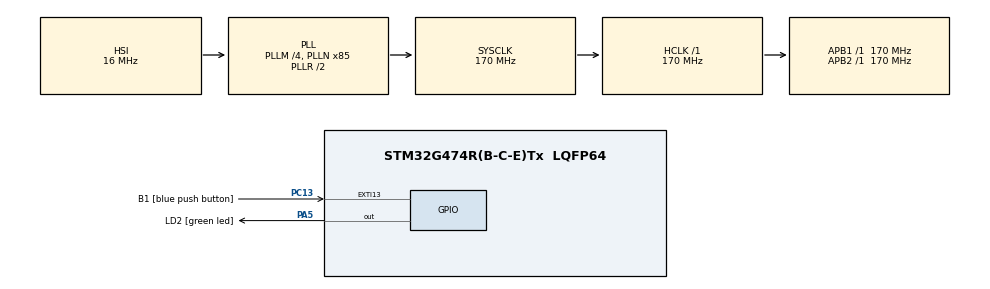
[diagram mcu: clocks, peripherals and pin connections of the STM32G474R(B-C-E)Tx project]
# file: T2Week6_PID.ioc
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ARM.CMSIS.5.7.0.CMSISJjCORE=true
ARM.CMSIS.5.7.0.CMSISJjDSP=Library
Mcu.Family=STM32G4
Mcu.Name=STM32G474R(B-C-E)Tx
Mcu.Package=LQFP64
NVIC.EXTI15_10_IRQn=true\:0\:0\:false\:false\:true\:true\:true\:true
NVIC.PriorityGroup=NVIC_PRIORITYGROUP_4
PA13.GPIO_Label=T_SWDIO
PA13.Mode=Trace_Asynchronous_SW
PA13.Signal=SYS_JTMS-SWDIO
PA14.GPIO_Label=T_SWCLK
PA14.Mode=Trace_Asynchronous_SW
PA14.Signal=SYS_JTCK-SWCLK
PA2.GPIO_Label=LPUART1_TX [STLINKV3E_VCP_RX]
PA2.Signal=LPUART1_TX
PA3.GPIO_Label=LPUART1_RX [STLINKV3E_VCP_TX]
PA3.Signal=LPUART1_RX
PA5.GPIO_Label=LD2 [green led]
PA5.Signal=GPIO_Output
PB3.GPIO_Label=T_SWO
PB3.Mode=Trace_Asynchronous_SW
PB3.Signal=SYS_JTDO-SWO
PC13.GPIO_Label=B1 [blue push button]
PC13.Signal=GPXTI13
PC14-OSC32_IN.GPIO_Label=RCC_OSC32_IN
PC14-OSC32_IN.Signal=RCC_OSC32_IN
PC15-OSC32_OUT.GPIO_Label=RCC_OSC32_OUT
PC15-OSC32_OUT.Signal=RCC_OSC32_OUT
PF0-OSC_IN.GPIO_Label=RCC_OSC_IN
PF0-OSC_IN.Signal=RCC_OSC_IN
PF1-OSC_OUT.GPIO_Label=RCC_OSC_OUT
PF1-OSC_OUT.Signal=RCC_OSC_OUT
ProjectManager.HeapSize=0x200
ProjectManager.StackSize=0x400
ProjectManager.TargetToolchain=STM32CubeIDE
RCC.ADC12Freq_Value=170000000
RCC.ADC345Freq_Value=170000000
RCC.AHBFreq_Value=170000000
RCC.APB1Freq_Value=170000000
RCC.APB1TimFreq_Value=170000000
RCC.APB2Freq_Value=170000000
RCC.APB2TimFreq_Value=170000000
RCC.CortexFreq_Value=170000000
RCC.EXTERNAL_CLOCK_VALUE=12288000
RCC.HCLKFreq_Value=170000000
RCC.HSE_VALUE=24000000
RCC.HSI48_VALUE=48000000
RCC.HSI_VALUE=16000000
RCC.LSE_VALUE=32768
RCC.PLLM=RCC_PLLM_DIV4
RCC.PLLN=85
RCC.RTCClockSelection=RCC_RTCCLKSOURCE_LSE
RCC.SYSCLKFreq_VALUE=170000000
RCC.SYSCLKSource=RCC_SYSCLKSOURCE_PLLCLK
RCC.USBFreq_Value=170000000
RCC.VCOOutputFreq_Value=340000000
VP_ARM.CMSIS_VS_CMSISJjCORE_5.4.0_5.7.0.Mode=CMSISJjCORE
VP_ARM.CMSIS_VS_CMSISJjDSP_1.8.0_5.7.0.Mode=CMSISJjDSP
VP_SYS_VS_DBSignals.Mode=DisableDeadBatterySignals
board=NUCLEO-G474RE

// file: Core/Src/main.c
/* USER CODE BEGIN Header */
/**
  ******************************************************************************
  * @file           : main.c
  * @brief          : Main program body
  ******************************************************************************
  * @attention
  *
  * Copyright (c) 2026 STMicroelectronics.
  * All rights reserved.
  *
  * This software is licensed under terms that can be found in the LICENSE file
  * in the root directory of this software component.
  * If no LICENSE file comes with this software, it is provided AS-IS.
  *
  ******************************************************************************
  */
/* USER CODE END Header */
#include "main.h"

/* USER CODE BEGIN Includes */
#include "arm_math.h"
/* USER CODE END Includes */

/* USER CODE BEGIN PV */
arm_pid_instance_f32 PID = {0};
float position = 0;
float setposition = 10;
float Vfeedback = 0;
/* USER CODE END PV */

void SystemClock_Config(void);
static void MX_GPIO_Init(void);
/* USER CODE BEGIN PFP */
float PlantSimulation(float VIn, float dt);
/* USER CODE END PFP */

int main(void)
{

  /* MCU Configuration--------------------------------------------------------*/

  /* Reset of all peripherals, Initializes the Flash interface and the Systick. */
  HAL_Init();

  /* Configure the system clock */
  SystemClock_Config();

  /* Initialize all configured peripherals */
  MX_GPIO_Init();
  /* USER CODE BEGIN 2 */
  PID.Kp = 0.045f;
  PID.Ki = 0.00001f;
  PID.Kd = 0.2f;
  arm_pid_init_f32(&PID, 1); // รีเซ็ตสถานะภายใน PID เป็น 0
  /* USER CODE END 2 */

  /* Infinite loop */
  while (1)
  {

    /* USER CODE BEGIN 3 */
	  // เช็คว่าค่า Kp, Ki หรือ Kd มีการเปลี่ยนแปลงจากเดิมหรือไม่?
	  static uint32_t timestamp = 0;
	      static GPIO_PinState B1[2] = {1, 1}; // เก็บสถา

	      // 1. ตรวจสอบปุ่มกด B1 (Falling Edge)
	      B1[0] = HAL_GPIO_ReadPin(B1_GPIO_Port, B1_Pin);
	      if(B1[0] == 0 && B1[1] == 1)
	      {
	          // เมื่อกดปุ่ม ให้รีเซ็ตและคำนวณสัมประสิทธิ์ PID ใหม่
	          arm_pid_init_f32(&PID, 0);
	      }
	      B1[1] = B1[0]; // จำสถานะปุ่มไว้ใช้รอบถัดไป

	      // 2. ลูปควบคุม PID (ทุกๆ 10ms หรือ 100Hz)
	      if(timestamp < HAL_GetTick())
	      {
	          timestamp = HAL_GetTick() + 10;

	          Vfeedback = arm_pid_f32(&PID, setposition - position);
	          position = PlantSimulation(Vfeedback, 0.1f);
	      }
	    }
  /* USER CODE END 3 */
}

void SystemClock_Config(void)
{
  RCC_OscInitTypeDef RCC_OscInitStruct = {0};
  RCC_ClkInitTypeDef RCC_ClkInitStruct = {0};

  /** Configure the main internal regulator output voltage
  */
  HAL_PWREx_ControlVoltageScaling(PWR_REGULATOR_VOLTAGE_SCALE1_BOOST);

  /** Initializes the RCC Oscillators according to the specified parameters
  * in the RCC_OscInitTypeDef structure.
  */
  RCC_OscInitStruct.OscillatorType = RCC_OSCILLATORTYPE_HSI;
  RCC_OscInitStruct.HSIState = RCC_HSI_ON;
  RCC_OscInitStruct.HSICalibrationValue = RCC_HSICALIBRATION_DEFAULT;
  RCC_OscInitStruct.PLL.PLLState = RCC_PLL_ON;
  RCC_OscInitStruct.PLL.PLLSource = RCC_PLLSOURCE_HSI;
  RCC_OscInitStruct.PLL.PLLM = RCC_PLLM_DIV4;
  RCC_OscInitStruct.PLL.PLLN = 85;
  RCC_OscInitStruct.PLL.PLLP = RCC_PLLP_DIV2;
  RCC_OscInitStruct.PLL.PLLQ = RCC_PLLQ_DIV2;
  RCC_OscInitStruct.PLL.PLLR = RCC_PLLR_DIV2;
  if (HAL_RCC_OscConfig(&RCC_OscInitStruct) != HAL_OK)
  {
    Error_Handler();
  }

  /** Initializes the CPU, AHB and APB buses clocks
  */
  RCC_ClkInitStruct.ClockType = RCC_CLOCKTYPE_HCLK|RCC_CLOCKTYPE_SYSCLK
                              |RCC_CLOCKTYPE_PCLK1|RCC_CLOCKTYPE_PCLK2;
  RCC_ClkInitStruct.SYSCLKSource = RCC_SYSCLKSOURCE_PLLCLK;
  RCC_ClkInitStruct.AHBCLKDivider = RCC_SYSCLK_DIV1;
  RCC_ClkInitStruct.APB1CLKDivider = RCC_HCLK_DIV1;
  RCC_ClkInitStruct.APB2CLKDivider = RCC_HCLK_DIV1;

  if (HAL_RCC_ClockConfig(&RCC_ClkInitStruct, FLASH_LATENCY_4) != HAL_OK)
  {
    Error_Handler();
  }
}

static void MX_GPIO_Init(void)
{
  GPIO_InitTypeDef GPIO_InitStruct = {0};

  /* GPIO Ports Clock Enable */
  __HAL_RCC_GPIOC_CLK_ENABLE();
  __HAL_RCC_GPIOF_CLK_ENABLE();
  __HAL_RCC_GPIOA_CLK_ENABLE();
  __HAL_RCC_GPIOB_CLK_ENABLE();

  /*Configure GPIO pin Output Level */
  HAL_GPIO_WritePin(LD2_GPIO_Port, LD2_Pin, GPIO_PIN_RESET);

  /*Configure GPIO pin : B1_Pin */
  GPIO_InitStruct.Pin = B1_Pin;
  GPIO_InitStruct.Mode = GPIO_MODE_IT_RISING;
  GPIO_InitStruct.Pull = GPIO_NOPULL;
  HAL_GPIO_Init(B1_GPIO_Port, &GPIO_InitStruct);

  /*Configure GPIO pins : LPUART1_TX_Pin LPUART1_RX_Pin */
  GPIO_InitStruct.Pin = LPUART1_TX_Pin|LPUART1_RX_Pin;
  GPIO_InitStruct.Mode = GPIO_MODE_AF_PP;
  GPIO_InitStruct.Pull = GPIO_NOPULL;
  GPIO_InitStruct.Speed = GPIO_SPEED_FREQ_LOW;
  GPIO_InitStruct.Alternate = GPIO_AF12_LPUART1;
  HAL_GPIO_Init(GPIOA, &GPIO_InitStruct);

  /*Configure GPIO pin : LD2_Pin */
  GPIO_InitStruct.Pin = LD2_Pin;
  GPIO_InitStruct.Mode = GPIO_MODE_OUTPUT_PP;
  GPIO_InitStruct.Pull = GPIO_NOPULL;
  GPIO_InitStruct.Speed = GPIO_SPEED_FREQ_LOW;
  HAL_GPIO_Init(LD2_GPIO_Port, &GPIO_InitStruct);

  /* EXTI interrupt init*/
  HAL_NVIC_SetPriority(EXTI15_10_IRQn, 0, 0);
  HAL_NVIC_EnableIRQ(EXTI15_10_IRQn);

}

/* USER CODE BEGIN 4 */
float PlantSimulation(float VIn, float dt) {
    static float speed = 0.0f;
    static float position = 0.0f;

    // ค่าคงที่ของมอเตอร์ (Constants)
    const float R = 2.0f;       // ความต้านทานภายใน (Ohms)
    const float Kt = 0.05f;     // Torque constant (Nm/A)
    const float Ke = 0.05f;     // Back-EMF constant (V/(rad/s))
    const float J = 0.001f;     // ความเฉื่อยของโรเตอร์ (kg*m^2)
    const float b = 0.0001f;    // แรงเสียดทานหนืด (Nm/(rad/s))

    // คำนวณหาแรงบิดสุทธิ
    float back_emf = speed * Ke;
    float current = (VIn - back_emf) / R;
    float motor_torque = current * Kt;
    float friction_torque = speed * b;
    float net_torque = motor_torque - friction_torque;

    // การคำนวณ Integration เพื่อหาตำแหน่ง (Position)
    float acc = net_torque / J; // ความเร่ง = แรงบิด / ความเฉื่อย
    speed += acc * dt;         // ความเร็ว = ความเร็วเดิม + (ความเร่ง * เวลา)
    position += speed * dt;    // ตำแหน่ง = ตำแหน่งเดิม + (ความเร็ว * เวลา)

    return position;
}
/* USER CODE END 4 */

void Error_Handler(void)
{
  __disable_irq();
  while (1)
  {
  }
}
